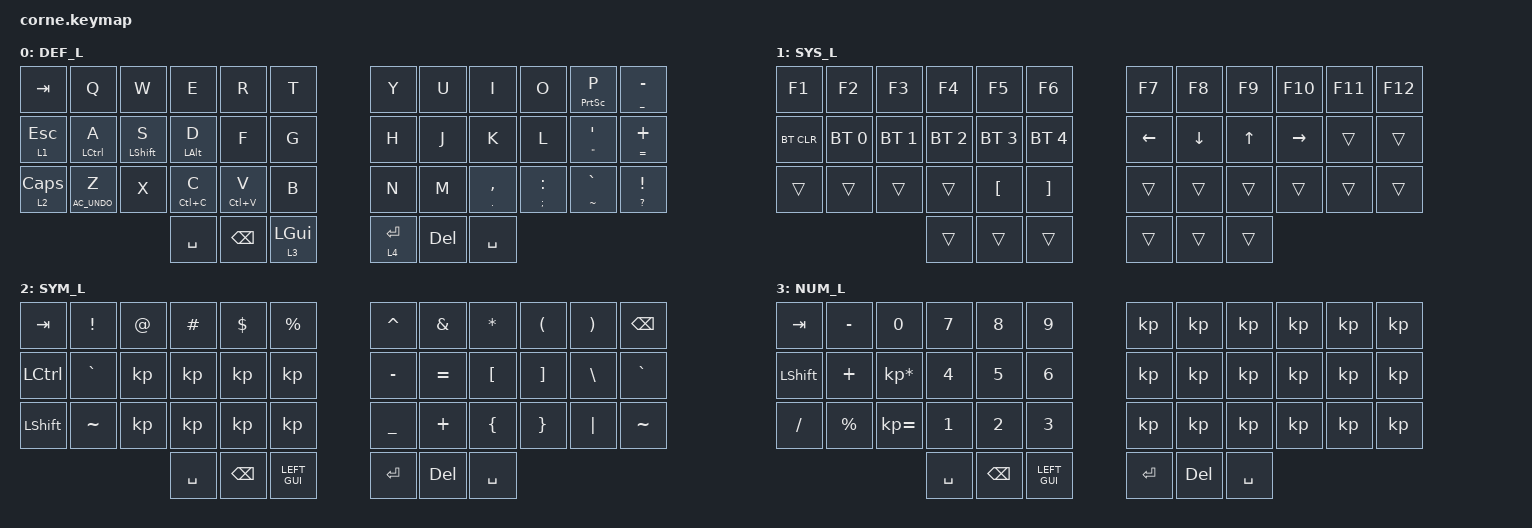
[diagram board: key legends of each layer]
/*
 * Copyright (c) 2020 The ZMK Contributors
 *
 * SPDX-License-Identifier: MIT
 */

#include <behaviors.dtsi>
#include <dt-bindings/zmk/bt.h>
#include <dt-bindings/zmk/keys.h>





// 0   1   2   3   4   5  │  6   7   8   9  10  11 │ │ LT5 LT4 LT3 LT2 LT1 LT0 │ RT0 RT1 RT2 RT3 RT4 RT5 │
//│ 12  13  14  15  16  17 │ 18  19  20  21  22  23 │ │ LM5 LM4 LM3 LM2 LM1 LM0 │ RM0 RM1 RM2 RM3 RM4 RM5 │
//│ 24  25  26  27  28  29 │ 30  31  32  33  34  35 │ │ LB5 LB4 LB3 LB2 LB1 LB0 │ RB0 RB1 RB2 RB3 RB4 RB5 │
//╰───────────╮ 36  37  38 │ 39  40  41 ╭─────────

/* Key Position Groups */
#define KEYS_L 0 1 2 3 4 5  12 13 14 15 16 17 24 25 26 27 28 29   // left-hand keys
#define KEYS_R 6 7 8 9 10 11 18 19 20 21 22 23 30 31 32 33 34 35  // right-hand keys
#define THUMBS 36  37  38  39  40  41                    // thumb keys

/*Behavior Settings*/

&sk {
  release-after-ms = <900>;
  quick-release;
};

&sl {
  release-after-ms = <250>;
};

&lt {  // layer-tap config
    flavor = "balanced";
    tapping-term-ms = <200>;
    require-prior-idle-ms = <150>;
    quick-tap-ms = <175>;
};

&mt {
    tapping-term-ms = <400>;
    quick-tap-ms = <175>;
    require-prior-idle-ms = <150>;
    flavor = "balanced";
};


/ {
    behaviors {
        mtl: mod_tap_left {
            compatible = "zmk,behavior-hold-tap";
            label = "MOD_TAP_LEFT";
            #binding-cells = <2>;
            flavor = "balanced";
            tapping-term-ms = <280>;
            quick-tap-ms = <175>;
            bindings = <&kp>, <&kp>;
            hold-trigger-key-positions = <KEYS_R THUMBS>;
            hold-trigger-on-release;
            global-quick-tap;
        };
        mtr: mod_tap_right {
            compatible = "zmk,behavior-hold-tap";
            label = "MOD_TAP_RIGHT";
            #binding-cells = <2>;
            flavor = "balanced";
            tapping-term-ms = <280>;
            quick-tap-ms = <175>;
            bindings = <&kp>, <&kp>;
            hold-trigger-key-positions = <KEYS_L THUMBS>;
            hold-trigger-on-release;
            global-quick-tap;
        };
    };

    conditional_layers {
        compatible = "zmk,conditional-layers";
        tri_layer {
            if-layers = <SYS_L SYM_L>;
            then-layer = <NUM_L>;
        };
    };

    
    combos {
        compatible = "zmk,combos";

        enter {timeout-ms = <50>;
            bindings = <&kp ENTER>;
            key-positions = <18 19>;
            layers = <0 1 2 3 4 5>;
        };

        bkt {timeout-ms = <50>;
            bindings = <&mt LBKT RBKT>;
            key-positions = <5 4>;
            layers = <0 1 2 3 4 5>;
        };

        par {timeout-ms = <50>;
            bindings = <&mt LPAR RPAR>;
            key-positions = <17 16>;
            layers = <0 1 2 3 4 5>;
        };

        brc {timeout-ms = <50>;
            bindings = <&mt LBRC RBRC>;
            key-positions = <29 28>;
            layers = <0 1 2 3 4 5>;
        };

        del {timeout-ms = <50>;
            bindings = <&kp DELETE>;
            key-positions = <15 16>;
            layers = <0 1 2 3 4 5>;
        };

        at {timeout-ms = <50>;
            bindings = <&kp AT>;
            key-positions = <12 13>;
            layers = <0 1 2 3 4 5>;
        };

        tag {timeout-ms = <50>;
            bindings = <&kp HASH>;
            key-positions = <5 17>;
            layers = <0 1 2 3 4 5>;
        };

        right {timeout-ms = <50>;
            bindings = <&kp RIGHT>;
            key-positions = <14 15>;
            layers = <0 1 2 3 4 5>;
        };

        left {timeout-ms = <50>;
            bindings = <&kp LEFT_ARROW>;
            key-positions = <13 14>;
            layers = <0 1 2 3 4 5>;
        };

        up {timeout-ms = <50>;
            bindings = <&kp UP_ARROW>;
            key-positions = <2 14>;
            layers = <0 1 2 3 4 5>;
        };

        down {timeout-ms = <50>;
            bindings = <&kp DOWN>;
            key-positions = <14 26>;
            layers = <0 1 2 3 4 5>;
        };

        leftbspc {timeout-ms = <50>;
            bindings = <&kp BACKSPACE>;
            key-positions = <0 1>;
            layers = <0 1 2 3 4 5>;
        };

        greater {timeout-ms = <50>;
            bindings = <&kp GREATER_THAN>;
            key-positions = <12 13>;
            layers = <0 1 2 3 4 5>;
        };

        less {timeout-ms = <50>;
            bindings = <&kp LESS_THAN>;
            key-positions = <24 25>;
            layers = <0 1 2 3 4 5>;
        };
    };

      keymap {
        compatible = "zmk,keymap";

       keymap {
        compatible = "zmk,keymap";

        DEF_L {
           
            bindings = <
&kp TAB       &kp Q                 &kp W              &kp E                &kp R        &kp T       &kp Y       &kp U        &kp I                &kp O                &mtl PRINTSCREEN P             &mt UNDER MINUS
&lt 1 ESC     &mtl LEFT_CONTROL A   &mtl LEFT_SHIFT S  &mtl LEFT_ALT D      &kp F        &kp G       &kp H       &kp J        &kp K                &kp L                &mt DOUBLE_QUOTES APOSTROPHE   &mt EQUAL PLUS
&lt 2 CAPS    &mtl C_AC_UNDO Z       &kp X             &mtl LC(C) C         &mtl LC(V) V  &kp B       &kp N       &kp M        &mt PERIOD COMMA     &mt SEMICOLON COLON  &mt TILDE GRAVE              &mt QMARK EXCL            
&kp SPACE     &kp BACKSPACE       &lt 3 LEFT_GUI   &lt 4 ENTER  &kp DELETE  &kp SPACE
            >;
        };

        SYS_L {
           
            bindings = <

&kp F1      &kp F2        &kp F3        &kp F4        &kp F5        &kp F6          &kp F7    &kp F8    &kp F9  &kp F10    &kp F11  &kp F12
&bt BT_CLR  &bt BT_SEL 0  &bt BT_SEL 1  &bt BT_SEL 2  &bt BT_SEL 3  &bt BT_SEL 4    &kp LEFT  &kp DOWN  &kp UP  &kp RIGHT  &trans   &trans
&trans      &trans        &trans        &trans        &kp LBKT      &kp RBKT        &trans    &trans    &trans  &trans     &trans   &trans
                                        &trans        &trans        &trans          &trans    &trans    &trans
            >;

        };

        SYM_L {
            bindings = <
&kp TAB    &kp EXCL  &kp AT  &kp HASH  &kp DLLR  &kp PRCNT    &kp CARET  &kp AMPS   &kp ASTRK  &kp LPAR  &kp RPAR  &kp BSPC
&kp LCTRL  &kp GRAVE &kp     &kp       &kp        &kp       &kp MINUS  &kp EQUAL  &kp LBKT   &kp RBKT  &kp BSLH  &kp GRAVE
&kp LSHFT  &kp TILDE &kp     &kp       &kp        &kp      &kp UNDER  &kp PLUS   &kp LBRC   &kp RBRC  &kp PIPE  &kp TILDE
&kp SPACE  &kp BACKSPACE    &LEFT_GUI   &kp ENTER    &kp DELETE     &kp SPACE
            >;
        };

        NUM_L {
            bindings = <
&kp TAB         &kp MINUS    &kp N0           &kp N7        &kp N8      &kp N9          &kp        &kp            &kp        &kp  &kp  &kp
&kp LEFT_SHIFT  &kp PLUS     &kp KP_MULTIPLY  &kp NUMBER_4  &kp N5      &kp NUMBER_6    &kp        &kp            &kp        &kp  &kp  &kp
&kp SLASH       &kp PERCENT  &kp KP_EQUAL     &kp NUMBER_1  &kp N2      &kp NUMBER_3    &kp        &kp            &kp        &kp  &kp  &kp
&kp SPACE  &kp BACKSPACE    &LEFT_GUI   &kp ENTER    &kp DELETE     &kp SPACE
            >;
        };
};
